# K1921VG1T register map
Vendor: NIIET; Series: K1921VGx; File version: 2.8
CPU: other r0p1, little endian, MPU, FPU, 4 interrupt priority bits
Registers are 32-bit, read-write, reset 0x0 unless marked. A register's access mark holds for its fields unless they carry their own. Offsets are from the block's base; [hi:lo] are bit positions; lines under a group give offsets from that group; {n}, {i} and the like mark numbered series.

## CAN — CAN control registers
Base 0x41010000
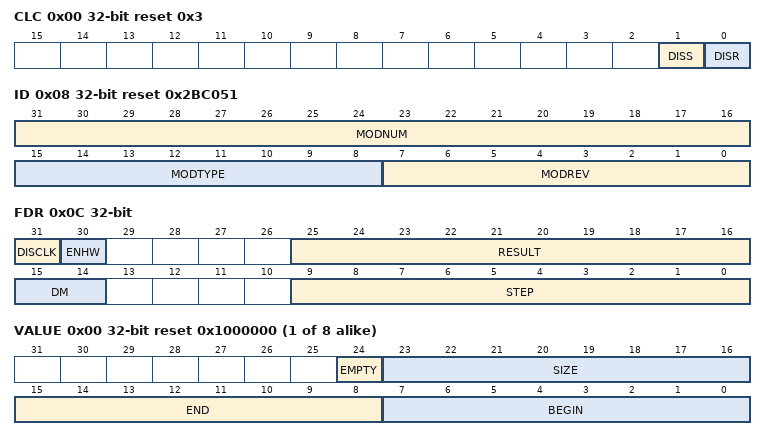
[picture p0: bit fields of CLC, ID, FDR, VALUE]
0x00 CLC reset 0x3 — Frequency control register
  [1] DISS ro — State CAN
  [0] DISR — OFF module CAN
0x08 ID reset 0x2BC051 — Identity register
  [31:16] MODNUM ro — Identification number CAN
  [15:8] MODTYPE ro — Digit capacity CAN
  [7:0] MODREV — Number of modifications of the CAN
0x0C FDR — Register divider
  [31] DISCLK — Disable bit internal clock
  [30] ENHW — Control bit synchronization
  [25:16] RESULT ro — Count frequency divider
  [15:14] DM — Mode setting of the frequency divider
    0=Disable (counter disabled); 1=NormalMode (normal operation mode); 2=DividerMode (divider operation mode)
  [9:0] STEP — Step divider
{0x100+4i} LIST[{i}] (i=0..7) group
  0x00 VALUE ro reset 0x1000000 — Register list0
    [24] EMPTY — Indicate empty list
    [23:16] SIZE — List size
    [15:8] END — Number of the last message object
    [7:0] BEGIN — Number of the first message object
{0x140+4i} MSPND[{i}] (i=0..7) group
  0x00 VALUE — Register waiting interrupts0
    [31:0] PND — Field waiting interrupts
{0x180+4i} MSID[{i}] (i=0..7) group
  0x00 VALUE ro reset 0x20 — Register messages index0
    [5:0] INDEX — Number field waiting bit
0x1C0 MSIMASK — Mask register message index
  [31:0] IM — Mask for waiting bit messages
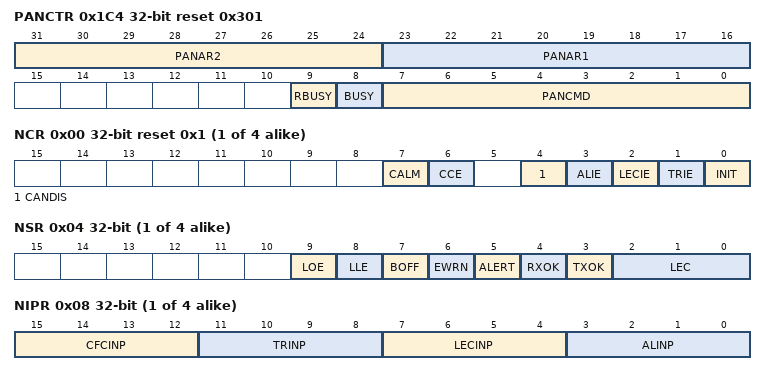
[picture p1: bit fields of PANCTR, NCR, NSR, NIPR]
0x1C4 PANCTR reset 0x301 — Register command panel
  [31:24] PANAR2 — Panel argument 2
  [23:16] PANAR1 — Panel argument 1
  [9] RBUSY ro — Busy flag panels arguments (running the command list, the result of which will be recorded in PANAR1 and PANAR2)
  [8] BUSY ro — Busy flag panels arguments (waiting to be written at the end of the command)
  [7:0] PANCMD — Command panel
0x1C8 MCR — Control register
  [15:12] MPSEL — Field task position after waiting message bit transmit / receive messages
0x1CC MITR wo — Interrupt register
  [15:0] IT — Field generate interrupt
{0x200+0x100*i} Node[{i}] (i=0..3) group
  0x00 NCR reset 0x1 — Register control node0
    [7] CALM — Activate the node analysis
    [6] CCE — Permission node configuration changes
    [4] CANDIS — Off node
    [3] ALIE — Enable interrupt ALERT from node
    [2] LECIE — Interrupt enable bit of the assembly when it detects the last error code
    [1] TRIE — Interrupt enable bit of the assembly at the end of the transmission / reception
    [0] INIT — Node initialization
  0x04 NSR — Register state node0
    [9] LOE — Error Flag Room list
    [8] LLE — Error flag list
    [7] BOFF ro — Status flag 'is disconnected from the bus'
    [6] EWRN ro — Flag critical errors
    [5] ALERT — Warning flag ALERT
    [4] RXOK — Flag successful reception of messages
    [3] TXOK — Flag successful message transmission
    [2:0] LEC — Last error code
      0=no error; 1=stuff error; 2=form error; 3=AckErr (acknowlegment error); 4=bit 1 error; 5=bit 0 error; 6=CRC error; 7=WriteEn (enable hardware write)
  0x08 NIPR — Interrupt pointer register node0
    [15:12] CFCINP — Frame counter interrupt node pointer - selects the interrupt line for a frame counter overflow
    [11:8] TRINP — Transfer OK interrupt node pointer - selects the interrupt line for transfer OK
    [7:4] LECINP — Last error code interrupt node pointer - selects the interrupt output line for LEC
    [3:0] ALINP — Alert interrupt node pointer - select the interrupt line for alert
  0x0C NPCR — Port control register node0
    [8] LBM — Enable mode Loop-Back
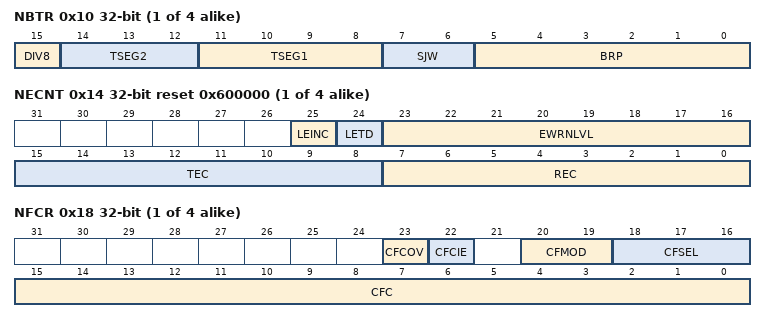
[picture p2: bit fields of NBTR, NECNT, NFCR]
  0x10 NBTR — Timing register bits 0
    [15] DIV8 — Frequency divider by 8
    [14:12] TSEG2 — Parameter 2
    [11:8] TSEG1 — Parameter 1
    [7:6] SJW — Transition width resynchronization
    [5:0] BRP — Prescaler rate
  0x14 NECNT reset 0x600000 — Counter error register node0
    [25] LEINC ro — Indicator increment at the last error
    [24] LETD ro — Flag last transmission errors
    [23:16] EWRNLVL — Error limit at which a flag is set in the register EWRN NSR
    [15:8] TEC — Counter field messaging error
    [7:0] REC — Receive Error Counter field messages
  0x18 NFCR — Register message counter node0
    [23] CFCOV — Counter overflow flag messages
    [22] CFCIE — Interrupt enable bit of the message counter
    [20:19] CFMOD — Field task mode message counter
    [18:16] CFSEL — Field parameter setting mode selected message counter
    [15:0] CFC — Field of the message counter
